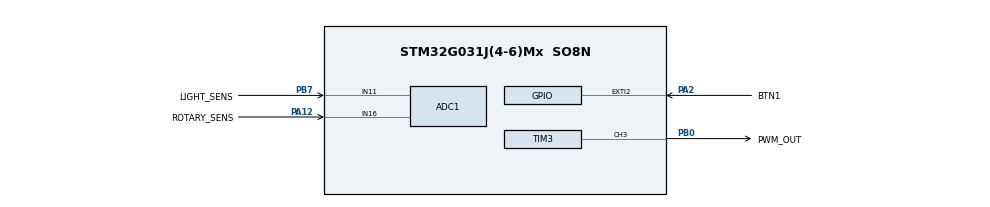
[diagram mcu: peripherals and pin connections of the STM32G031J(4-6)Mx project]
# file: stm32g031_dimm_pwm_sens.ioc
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ADC1.NbrOfConversion=1
ADC1.NbrOfConversionFlag=0
ADC1.OversamplingMode=DISABLE
ADC1.SamplingTimeCommon1=ADC_SAMPLETIME_79CYCLES_5
ADC1.SelectedChannel=ADC_CHANNEL_11|ADC_CHANNEL_16
ADC1.Sequencer=NOT_FULLY_CONFIGURABLE
ADC1.master=1
Mcu.Family=STM32G0
Mcu.Name=STM32G031J(4-6)Mx
Mcu.Package=SO8N
NVIC.ADC1_IRQn=true\:0\:0\:false\:false\:true\:true\:true
NVIC.TIM14_IRQn=true\:0\:0\:false\:false\:true\:true\:true
NVIC.TIM3_IRQn=true\:0\:0\:false\:false\:true\:true\:true
PA12\ [PA10].GPIO_Label=ROTARY_SENS
PA12\ [PA10].Mode=IN16
PA12\ [PA10].Signal=ADC1_IN16
PA13.Mode=Serial_Wire
PA13.Signal=SYS_SWDIO
PA14-BOOT0.Mode=Serial_Wire
PA14-BOOT0.Signal=SYS_SWCLK
PA2.GPIO_Label=BTN1
PA2.GPIO_ModeDefaultEXTI=GPIO_MODE_IT_FALLING
PA2.GPIO_PuPd=GPIO_PULLUP
PA2.Signal=GPXTI2
PB0.GPIO_Label=PWM_OUT
PB0.Signal=S_TIM3_CH3
PB7.GPIO_Label=LIGHT_SENS
PB7.Mode=IN11
PB7.Signal=ADC1_IN11
ProjectManager.HeapSize=0x200
ProjectManager.StackSize=0x400
ProjectManager.TargetToolchain=STM32CubeIDE
RCC.ADCCLockSelection=RCC_ADCCLKSOURCE_PLLADC
RCC.ADCFreq_Value=8000000
RCC.AHBFreq_Value=64000000
RCC.CortexFreq_Value=64000000
RCC.EXTERNAL_CLOCK_VALUE=12288000
RCC.HCLKFreq_Value=64000000
RCC.HSE_VALUE=8000000
RCC.HSI_VALUE=16000000
RCC.LSE_VALUE=32768
RCC.PLLP=RCC_PLLP_DIV16
RCC.SYSCLKFreq_VALUE=64000000
RCC.SYSCLKSource=RCC_SYSCLKSOURCE_PLLCLK
RCC.VCOOutputFreq_Value=128000000
SH.S_TIM3_CH3.0=TIM3_CH3,PWM Generation3 CH3
TIM14.Channel=TIM_CHANNEL_1
TIM14.Period=64000
TIM3.Channel-PWM\ Generation3\ CH3=TIM_CHANNEL_3
TIM3.Period=1280-1
TIM3.Pulse-PWM\ Generation3\ CH3=640-1
VP_TIM14_VS_ClockSourceINT.Mode=Enable_Timer
VP_TIM14_VS_no_output1.Mode=Output Compare1 No Output
VP_TIM3_VS_ClockSourceINT.Mode=Internal
board=custom

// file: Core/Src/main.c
/* USER CODE BEGIN Header */
/**
  ******************************************************************************
  * @file           : main.c
  * @brief          : Main program body
  ******************************************************************************
  * @attention
  *
  * <h2><center>&copy; Copyright (c) 2021 STMicroelectronics.
  * All rights reserved.</center></h2>
  *
  * This software component is licensed by ST under BSD 3-Clause license,
  * the "License"; You may not use this file except in compliance with the
  * License. You may obtain a copy of the License at:
  *                        opensource.org/licenses/BSD-3-Clause
  *
  ******************************************************************************
  */
/* USER CODE END Header */
#include "main.h"
#include "adc.h"
#include "tim.h"
#include "gpio.h"

/* USER CODE BEGIN Includes */
#include "control.h"
/* USER CODE END Includes */

void SystemClock_Config(void);

int main(void)
{

  /* MCU Configuration--------------------------------------------------------*/

  /* Reset of all peripherals, Initializes the Flash interface and the Systick. */

  LL_APB2_GRP1_EnableClock(LL_APB2_GRP1_PERIPH_SYSCFG);
  LL_APB1_GRP1_EnableClock(LL_APB1_GRP1_PERIPH_PWR);

  /* System interrupt init*/
  /* SysTick_IRQn interrupt configuration */
  NVIC_SetPriority(SysTick_IRQn, 3);

  /* Configure the system clock */
  SystemClock_Config();

  /* Initialize all configured peripherals */
  MX_GPIO_Init();
  MX_TIM3_Init();
  MX_ADC1_Init();
  MX_TIM14_Init();
  /* USER CODE BEGIN 2 */
//timer 16 init here, later throw it into separate function:

  //pwm 50kHz timer config:
  LL_TIM_EnableIT_UPDATE(TIM3);
  LL_TIM_CC_EnableChannel(TIM3, LL_TIM_CHANNEL_CH3);
  LL_TIM_EnableCounter(TIM3);
  //event timebase timr config 1kHz:
  LL_TIM_EnableIT_UPDATE(TIM14);
  LL_TIM_CC_EnableChannel(TIM14, LL_TIM_CHANNEL_CH1);
  LL_TIM_EnableCounter(TIM14);
  //adc config: (single conversion EOC flag ISR)
//  LL_ADC_EnableInternalRegulator(ADC1);
  LL_ADC_EnableIT_EOC(ADC1);
  LL_ADC_Enable(ADC1);
  LL_mDelay(1);
  /* USER CODE END 2 */

  /* Infinite loop */
  /* USER CODE BEGIN WHILE */
  while (1)
  {
	  LL_ADC_REG_StartConversion(ADC1);
	  system_ctrl();
	  LL_mDelay(10);
//	  LL_GPIO_TogglePin(LD1_GPIO_Port, LD1_Pin);
    /* USER CODE END WHILE */

  }
}

void SystemClock_Config(void)
{
  LL_FLASH_SetLatency(LL_FLASH_LATENCY_2);
  while(LL_FLASH_GetLatency() != LL_FLASH_LATENCY_2)
  {
  }

  /* HSI configuration and activation */
  LL_RCC_HSI_Enable();
  while(LL_RCC_HSI_IsReady() != 1)
  {
  }

  /* Main PLL configuration and activation */
  LL_RCC_PLL_ConfigDomain_ADC(LL_RCC_PLLSOURCE_HSI, LL_RCC_PLLM_DIV_1, 8, LL_RCC_PLLP_DIV_16);
  LL_RCC_PLL_EnableDomain_ADC();
  LL_RCC_PLL_ConfigDomain_SYS(LL_RCC_PLLSOURCE_HSI, LL_RCC_PLLM_DIV_1, 8, LL_RCC_PLLR_DIV_2);
  LL_RCC_PLL_Enable();
  LL_RCC_PLL_EnableDomain_SYS();
  while(LL_RCC_PLL_IsReady() != 1)
  {
  }

  /* Set AHB prescaler*/
  LL_RCC_SetAHBPrescaler(LL_RCC_SYSCLK_DIV_1);

  /* Sysclk activation on the main PLL */
  LL_RCC_SetSysClkSource(LL_RCC_SYS_CLKSOURCE_PLL);
  while(LL_RCC_GetSysClkSource() != LL_RCC_SYS_CLKSOURCE_STATUS_PLL)
  {
  }

  /* Set APB1 prescaler*/
  LL_RCC_SetAPB1Prescaler(LL_RCC_APB1_DIV_1);

  LL_Init1msTick(64000000);

  /* Update CMSIS variable (which can be updated also through SystemCoreClockUpdate function) */
  LL_SetSystemCoreClock(64000000);
  LL_RCC_SetADCClockSource(LL_RCC_ADC_CLKSOURCE_PLL);
}

void Error_Handler(void)
{
  __disable_irq();
  while (1)
  {
  }
}

/************************ (C) COPYRIGHT STMicroelectronics *****END OF FILE****/
